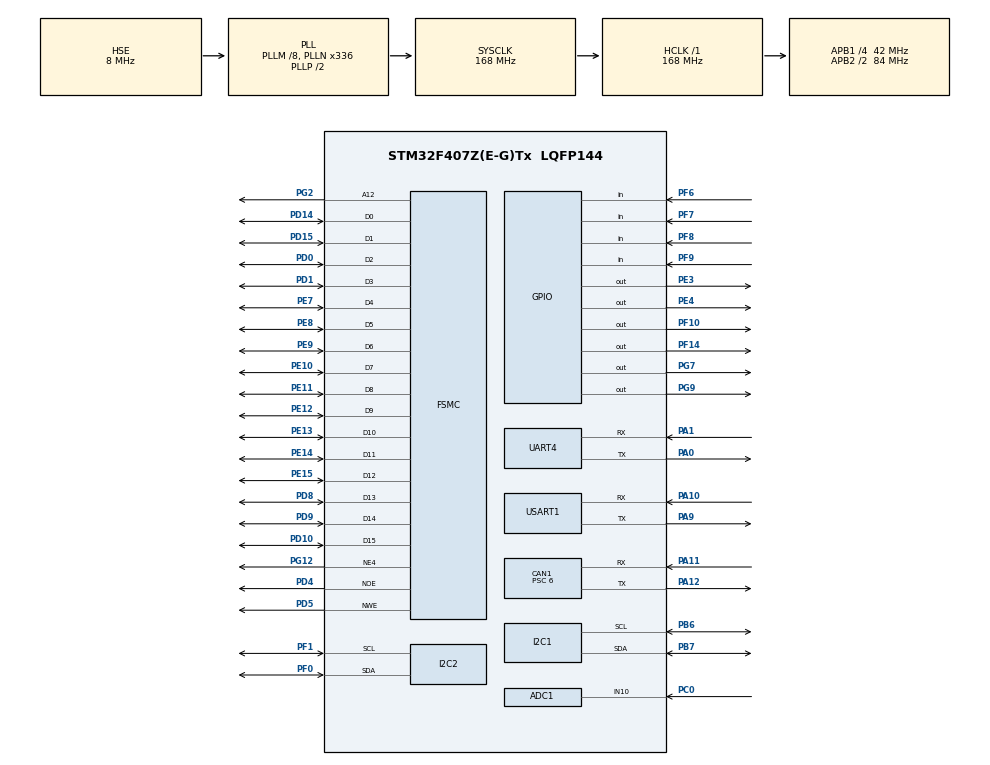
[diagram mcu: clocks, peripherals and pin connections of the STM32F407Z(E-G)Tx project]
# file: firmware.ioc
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ADC1.Channel-0\#ChannelRegularConversion=ADC_CHANNEL_10
ADC1.NbrOfConversionFlag=1
ADC1.Rank-0\#ChannelRegularConversion=1
ADC1.SamplingTime-0\#ChannelRegularConversion=ADC_SAMPLETIME_480CYCLES
ADC1.master=1
CAN1.ABOM=ENABLE
CAN1.BS1=CAN_BS1_10TQ
CAN1.BS2=CAN_BS2_3TQ
CAN1.CalculateBaudRate=500000
CAN1.CalculateTimeBit=2000
CAN1.CalculateTimeQuantum=142.85714285714286
CAN1.NART=ENABLE
CAN1.Prescaler=6
FREERTOS.Tasks01=defaultTask,0,128,StartDefaultTask,Default,NULL,Dynamic,NULL,NULL
FREERTOS.configTOTAL_HEAP_SIZE=20480
FSMC.AddressHoldTime1=0
FSMC.AddressSetupTime1=15
FSMC.BusTurnAroundDuration1=0
FSMC.DataSetupTime1=60
FSMC.ExtendedAddressHoldTime1=0
FSMC.ExtendedAddressSetupTime1=9
FSMC.ExtendedBusTurnAroundDuration1=0
FSMC.ExtendedDataSetupTime1=8
FSMC.ExtendedMode1=FSMC_EXTENDED_MODE_ENABLE
Mcu.Family=STM32F4
Mcu.Name=STM32F407Z(E-G)Tx
Mcu.Package=LQFP144
NVIC.PriorityGroup=NVIC_PRIORITYGROUP_4
NVIC.TIM6_DAC_IRQn=true\:15\:0\:false\:false\:true\:false\:false\:true\:true
NVIC.TimeBase=TIM6_DAC_IRQn
NVIC.TimeBaseIP=TIM6
NVIC.UART4_IRQn=true\:5\:0\:false\:false\:true\:true\:true\:true\:true
NVIC.USART1_IRQn=true\:5\:0\:false\:false\:true\:true\:true\:true\:true
PA0-WKUP.Mode=Asynchronous
PA0-WKUP.Signal=UART4_TX
PA1.Mode=Asynchronous
PA1.Signal=UART4_RX
PA10.Mode=Asynchronous
PA10.Signal=USART1_RX
PA11.Mode=CAN_Activate
PA11.Signal=CAN1_RX
PA12.Mode=CAN_Activate
PA12.Signal=CAN1_TX
PA13.Mode=Serial_Wire
PA13.Signal=SYS_JTMS-SWDIO
PA14.Mode=Serial_Wire
PA14.Signal=SYS_JTCK-SWCLK
PA9.Mode=Asynchronous
PA9.Signal=USART1_TX
PB6.Mode=I2C
PB6.Signal=I2C1_SCL
PB7.Mode=I2C
PB7.Signal=I2C1_SDA
PC0.Signal=ADCx_IN10
PD0.Signal=FSMC_D2_DA2
PD1.Signal=FSMC_D3_DA3
PD10.Signal=FSMC_D15_DA15
PD14.Signal=FSMC_D0_DA0
PD15.Signal=FSMC_D1_DA1
PD4.Signal=FSMC_NOE
PD5.Signal=FSMC_NWE
PD8.Signal=FSMC_D13_DA13
PD9.Signal=FSMC_D14_DA14
PE10.Signal=FSMC_D7_DA7
PE11.Signal=FSMC_D8_DA8
PE12.Signal=FSMC_D9_DA9
PE13.Signal=FSMC_D10_DA10
PE14.Signal=FSMC_D11_DA11
PE15.Signal=FSMC_D12_DA12
PE3.GPIO_ModeDefaultOutputPP=GPIO_MODE_OUTPUT_PP
PE3.GPIO_PuPd=GPIO_NOPULL
PE3.GPIO_Speed=GPIO_SPEED_FREQ_VERY_HIGH
PE3.PinState=GPIO_PIN_SET
PE3.Signal=GPIO_Output
PE4.GPIO_ModeDefaultOutputPP=GPIO_MODE_OUTPUT_PP
PE4.GPIO_PuPd=GPIO_NOPULL
PE4.GPIO_Speed=GPIO_SPEED_FREQ_VERY_HIGH
PE4.PinState=GPIO_PIN_SET
PE4.Signal=GPIO_Output
PE7.Signal=FSMC_D4_DA4
PE8.Signal=FSMC_D5_DA5
PE9.Signal=FSMC_D6_DA6
PF0.Mode=I2C
PF0.Signal=I2C2_SDA
PF1.Mode=I2C
PF1.Signal=I2C2_SCL
PF10.Signal=GPIO_Output
PF14.Signal=GPIO_Output
PF6.GPIO_Mode=GPIO_MODE_INPUT
PF6.GPIO_PuPd=GPIO_PULLUP
PF6.Signal=GPIO_Input
PF7.GPIO_Mode=GPIO_MODE_INPUT
PF7.GPIO_PuPd=GPIO_PULLUP
PF7.Signal=GPIO_Input
PF8.GPIO_Mode=GPIO_MODE_INPUT
PF8.GPIO_PuPd=GPIO_PULLUP
PF8.Signal=GPIO_Input
PF9.GPIO_Mode=GPIO_MODE_INPUT
PF9.GPIO_PuPd=GPIO_PULLUP
PF9.Signal=GPIO_Input
PG12.Mode=NorPsramChipSelect4_1
PG12.Signal=FSMC_NE4
PG2.Signal=FSMC_A12
PG7.Signal=GPIO_Output
PG9.GPIO_ModeDefaultOutputPP=GPIO_MODE_OUTPUT_PP
PG9.GPIO_PuPd=GPIO_NOPULL
PG9.GPIO_Speed=GPIO_SPEED_FREQ_VERY_HIGH
PG9.PinState=GPIO_PIN_SET
PG9.Signal=GPIO_Output
PH0-OSC_IN.Mode=HSE-External-Oscillator
PH0-OSC_IN.Signal=RCC_OSC_IN
PH1-OSC_OUT.Mode=HSE-External-Oscillator
PH1-OSC_OUT.Signal=RCC_OSC_OUT
ProjectManager.HeapSize=0x800
ProjectManager.StackSize=0x800
ProjectManager.TargetToolchain=MDK-ARM V5.32
RCC.48MHZClocksFreq_Value=84000000
RCC.AHBFreq_Value=168000000
RCC.APB1CLKDivider=RCC_HCLK_DIV4
RCC.APB1Freq_Value=42000000
RCC.APB1TimFreq_Value=84000000
RCC.APB2CLKDivider=RCC_HCLK_DIV2
RCC.APB2Freq_Value=84000000
RCC.APB2TimFreq_Value=168000000
RCC.CortexFreq_Value=168000000
RCC.HCLKFreq_Value=168000000
RCC.HSE_VALUE=8000000
RCC.HSI_VALUE=16000000
RCC.LSE_VALUE=32768
RCC.PLLM=8
RCC.PLLN=336
RCC.PLLSourceVirtual=RCC_PLLSOURCE_HSE
RCC.SYSCLKFreq_VALUE=168000000
RCC.SYSCLKSource=RCC_SYSCLKSOURCE_PLLCLK
RCC.VCOOutputFreq_Value=336000000
SH.ADCx_IN10.0=ADC1_IN10,IN10
SH.FSMC_A12.0=FSMC_A12,A12_1
SH.FSMC_D0_DA0.0=FSMC_D0,16b-d1
SH.FSMC_D10_DA10.0=FSMC_D10,16b-d1
SH.FSMC_D11_DA11.0=FSMC_D11,16b-d1
SH.FSMC_D12_DA12.0=FSMC_D12,16b-d1
SH.FSMC_D13_DA13.0=FSMC_D13,16b-d1
SH.FSMC_D14_DA14.0=FSMC_D14,16b-d1
SH.FSMC_D15_DA15.0=FSMC_D15,16b-d1
SH.FSMC_D1_DA1.0=FSMC_D1,16b-d1
SH.FSMC_D2_DA2.0=FSMC_D2,16b-d1
SH.FSMC_D3_DA3.0=FSMC_D3,16b-d1
SH.FSMC_D4_DA4.0=FSMC_D4,16b-d1
SH.FSMC_D5_DA5.0=FSMC_D5,16b-d1
SH.FSMC_D6_DA6.0=FSMC_D6,16b-d1
SH.FSMC_D7_DA7.0=FSMC_D7,16b-d1
SH.FSMC_D8_DA8.0=FSMC_D8,16b-d1
SH.FSMC_D9_DA9.0=FSMC_D9,16b-d1
SH.FSMC_NOE.0=FSMC_NOE,Lcd1
SH.FSMC_NWE.0=FSMC_NWE,Lcd1
STMicroelectronics.X-CUBE-AI.10.2.1.ActivationBufferSizeList=0
STMicroelectronics.X-CUBE-AI.10.2.1.ActivationBuffers=NULL
STMicroelectronics.X-CUBE-AI.10.2.1.ApplicationCcDeviceJjApplication=ApplicationTemplate
STMicroelectronics.X-CUBE-AI.10.2.1.HeapSize=0x800
STMicroelectronics.X-CUBE-AI.10.2.1.LatestDirectoryUsed-df4ddd3f1c85c4e8554ecd7a328a6c66531a2f60926d6c9770add6e9624a0a95=E\:\\Develop\\SignalsAndSystems\\Lab7\\ai\\model
STMicroelectronics.X-CUBE-AI.10.2.1.MaximumNumberOfInputLayer=1
STMicroelectronics.X-CUBE-AI.10.2.1.MaximumNumberOfOutputLayer=1
STMicroelectronics.X-CUBE-AI.10.2.1.ModelActualCompression-df4ddd3f1c85c4e8554ecd7a328a6c66531a2f60926d6c9770add6e9624a0a95=0.0
STMicroelectronics.X-CUBE-AI.10.2.1.ModelCompression-df4ddd3f1c85c4e8554ecd7a328a6c66531a2f60926d6c9770add6e9624a0a95=None
STMicroelectronics.X-CUBE-AI.10.2.1.ModelFlashOccupation-df4ddd3f1c85c4e8554ecd7a328a6c66531a2f60926d6c9770add6e9624a0a95=0
STMicroelectronics.X-CUBE-AI.10.2.1.ModelHashList=df4ddd3f1c85c4e8554ecd7a328a6c66531a2f60926d6c9770add6e9624a0a95
STMicroelectronics.X-CUBE-AI.10.2.1.ModelKind-df4ddd3f1c85c4e8554ecd7a328a6c66531a2f60926d6c9770add6e9624a0a95=KERAS
STMicroelectronics.X-CUBE-AI.10.2.1.ModelMacc-df4ddd3f1c85c4e8554ecd7a328a6c66531a2f60926d6c9770add6e9624a0a95=0
STMicroelectronics.X-CUBE-AI.10.2.1.ModelName-df4ddd3f1c85c4e8554ecd7a328a6c66531a2f60926d6c9770add6e9624a0a95=network
STMicroelectronics.X-CUBE-AI.10.2.1.ModelNameList=network
STMicroelectronics.X-CUBE-AI.10.2.1.ModelRamOccupation-df4ddd3f1c85c4e8554ecd7a328a6c66531a2f60926d6c9770add6e9624a0a95=0
STMicroelectronics.X-CUBE-AI.10.2.1.ModelStructureFile-df4ddd3f1c85c4e8554ecd7a328a6c66531a2f60926d6c9770add6e9624a0a95=E\:\\Develop\\SignalsAndSystems\\Lab7\\ai\\model\\model.h5
STMicroelectronics.X-CUBE-AI.10.2.1.ModelType-df4ddd3f1c85c4e8554ecd7a328a6c66531a2f60926d6c9770add6e9624a0a95=STM32Cube.AI MCU runtime
STMicroelectronics.X-CUBE-AI.10.2.1.ReadyForCodeGeneration=false
STMicroelectronics.X-CUBE-AI.10.2.1.StackSize=0x800
STMicroelectronics.X-CUBE-AI.10.2.1.WorkingBufferStartAddrList=0xFFFFFFFF
STMicroelectronics.X-CUBE-AI.10.2.1.XAaCUBEAaAICcArtificialOoIntelligenceJjCore=true
STMicroelectronics.X-CUBE-AI.10.2.1.copyWeightToRam=false
STMicroelectronics.X-CUBE-AI.10.2.1.customLayerConfigEnabled=false
STMicroelectronics.X-CUBE-AI.10.2.1.noOnnxIoTranspose=false
STMicroelectronics.X-CUBE-AI.10.2.1.useInputAllocation=true
STMicroelectronics.X-CUBE-AI.10.2.1.useOutputAllocation=true
UART4.VirtualMode=Asynchronous
USART1.VirtualMode=VM_ASYNC
VP_FREERTOS_VS_CMSIS_V1.Mode=CMSIS_V1
VP_STMicroelectronics.X-CUBE-AI_VS_ArtificialOoIntelligenceJjXAaCUBEAaAI_10.2.1.Mode=ArtificialOoIntelligenceJjXAaCUBEAaAI
VP_STMicroelectronics.X-CUBE-AI_VS_DeviceJjApplication_10.2.1.Mode=DeviceJjApplication
VP_SYS_VS_tim6.Mode=TIM6
board=custom

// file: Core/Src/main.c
/* USER CODE BEGIN Header */
/**
  ******************************************************************************
  * @file           : main.c
  * @brief          : Main program body
  ******************************************************************************
  * @attention
  *
  * Copyright (c) 2026 STMicroelectronics.
  * All rights reserved.
  *
  * This software is licensed under terms that can be found in the LICENSE file
  * in the root directory of this software component.
  * If no LICENSE file comes with this software, it is provided AS-IS.
  *
  ******************************************************************************
  */
/* USER CODE END Header */
#include "main.h"
#include "cmsis_os.h"
#include "adc.h"
#include "can.h"
#include "i2c.h"
#include "usart.h"
#include "gpio.h"
#include "fsmc.h"
/* ★ 实验七：CubeMX 加了 `#include "app_x-cube-ai.h"` + `MX_X_CUBE_AI_Init()`，
   指向 X-CUBE-AI 的 ApplicationTemplate（app_x-cube-ai.c）。
   我们**不用那个模板** —— 它是"跑一遍内嵌测试数据"的演示 app，
   和本工程的 AiTask/ai_model.c（1Hz 判本板+对板）重复。
   所以这里把两处都去掉，网络由 firmware/USER/AI/ai_model.c 自己创建：
   少一份网络实例（省 128B 激活区），也少一条容易搞混的初始化路径。
   （app_x-cube-ai.c 留在 X-CUBE-AI/ 目录里备查，不参与编译。）*/

/* USER CODE BEGIN Includes */
#include "app.h"
/* USER CODE END Includes */

void SystemClock_Config(void);
void MX_FREERTOS_Init(void);

int main(void)
{

  /* MCU Configuration--------------------------------------------------------*/

  /* Reset of all peripherals, Initializes the Flash interface and the Systick. */
  HAL_Init();

  /* Configure the system clock */
  SystemClock_Config();

  /* Initialize all configured peripherals */
  MX_GPIO_Init();
  MX_I2C1_Init();
  MX_UART4_Init();
  MX_USART1_UART_Init();
  MX_FSMC_Init();
  MX_ADC1_Init();
  MX_CAN1_Init();
  MX_I2C2_Init();
  /* ★ 实验七：原 `MX_X_CUBE_AI_Init();`（X-CUBE-AI 的 ApplicationTemplate）
     已去掉 —— 网络改由 USER/AI/ai_model.c 自己创建，理由见文件头注释。*/
  /* USER CODE BEGIN 2 */

  App_Init();
  /* USER CODE END 2 */

  /* Call init function for freertos objects (in cmsis_os2.c) */
  MX_FREERTOS_Init();

  /* Start scheduler */
  osKernelStart();

  /* We should never get here as control is now taken by the scheduler */

  /* Infinite loop */
  while (1)
  {

    /* USER CODE BEGIN 3 */
    App_Loop();
  }
  /* USER CODE END 3 */
}

void SystemClock_Config(void)
{
  RCC_OscInitTypeDef RCC_OscInitStruct = {0};
  RCC_ClkInitTypeDef RCC_ClkInitStruct = {0};

  /** Configure the main internal regulator output voltage
  */
  __HAL_RCC_PWR_CLK_ENABLE();
  __HAL_PWR_VOLTAGESCALING_CONFIG(PWR_REGULATOR_VOLTAGE_SCALE1);

  /** Initializes the RCC Oscillators according to the specified parameters
  * in the RCC_OscInitTypeDef structure.
  */
  RCC_OscInitStruct.OscillatorType = RCC_OSCILLATORTYPE_HSE;
  RCC_OscInitStruct.HSEState = RCC_HSE_ON;
  RCC_OscInitStruct.PLL.PLLState = RCC_PLL_ON;
  RCC_OscInitStruct.PLL.PLLSource = RCC_PLLSOURCE_HSE;
  RCC_OscInitStruct.PLL.PLLM = 8;
  RCC_OscInitStruct.PLL.PLLN = 336;
  RCC_OscInitStruct.PLL.PLLP = RCC_PLLP_DIV2;
  RCC_OscInitStruct.PLL.PLLQ = 4;
  if (HAL_RCC_OscConfig(&RCC_OscInitStruct) != HAL_OK)
  {
    Error_Handler();
  }

  /** Initializes the CPU, AHB and APB buses clocks
  */
  RCC_ClkInitStruct.ClockType = RCC_CLOCKTYPE_HCLK|RCC_CLOCKTYPE_SYSCLK
                              |RCC_CLOCKTYPE_PCLK1|RCC_CLOCKTYPE_PCLK2;
  RCC_ClkInitStruct.SYSCLKSource = RCC_SYSCLKSOURCE_PLLCLK;
  RCC_ClkInitStruct.AHBCLKDivider = RCC_SYSCLK_DIV1;
  RCC_ClkInitStruct.APB1CLKDivider = RCC_HCLK_DIV4;
  RCC_ClkInitStruct.APB2CLKDivider = RCC_HCLK_DIV2;

  if (HAL_RCC_ClockConfig(&RCC_ClkInitStruct, FLASH_LATENCY_5) != HAL_OK)
  {
    Error_Handler();
  }
}

void HAL_TIM_PeriodElapsedCallback(TIM_HandleTypeDef *htim)
{
  if (htim->Instance == TIM6)
  {
    HAL_IncTick();
  }
}

void Error_Handler(void)
{
  /* USER CODE BEGIN Error_Handler_Debug */
  /* ★ 不要在这儿静默死循环：CubeMX 默认的"关中断 + while(1)"会让现场完全看不出
     是哪个外设初始化失败 —— 串口没输出、屏不动、LED 也不闪，只能靠猜。
     改成**闪板载 LED0（PE3）**：直接写寄存器，不依赖 HAL / 中断 / 时基。
        LED 快闪 = 卡在初始化阶段（MX_GPIO_Init 之后的任何外设失败都会走到这）。
     本段在 USER CODE 区，CubeMX 重新生成代码会原样保留。 */
  __disable_irq();
  for (;;)
  {
    volatile u32 d;
    GPIOE->ODR ^= GPIO_PIN_3;          /* LED0：闪 = 初始化失败 */
    for (d = 0U; d < 20000000U; d++)
    {
      /* 约 120ms 半周期（168MHz 下）*/
    }
  }
  /* USER CODE END Error_Handler_Debug */
}
